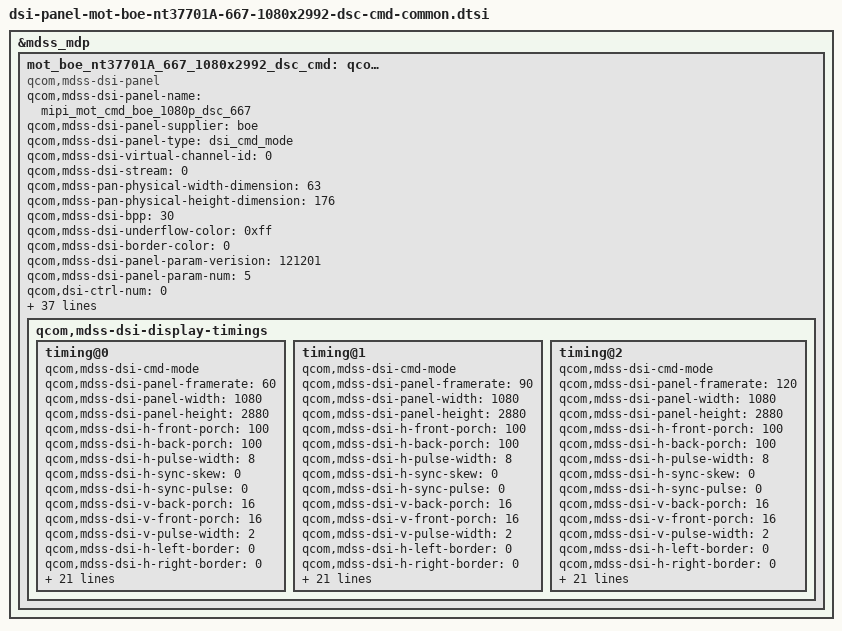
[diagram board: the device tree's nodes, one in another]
/*
 * Copyright (c) 2022, The Linux Foundation. All rights reserved.
 *
 * This program is free software; you can redistribute it and/or modify
 * it under the terms of the GNU General Public License version 2 and
 * only version 2 as published by the Free Software Foundation.
 *
 * This program is distributed in the hope that it will be useful,
 * but WITHOUT ANY WARRANTY; without even the implied warranty of
 * MERCHANTABILITY or FITNESS FOR A PARTICULAR PURPOSE.  See the
 * GNU General Public License for more details.
 */

&mdss_mdp {
mot_boe_nt37701A_667_1080x2992_dsc_cmd: qcom,mdss_dsi_mot_boe_nt37701A_667_1080x2992_dsc_cmd {
compatible = "qcom,mdss-dsi-panel";
qcom,mdss-dsi-panel-name = "mipi_mot_cmd_boe_1080p_dsc_667";
qcom,mdss-dsi-panel-supplier = "boe";
qcom,mdss-dsi-panel-type = "dsi_cmd_mode";
qcom,mdss-dsi-virtual-channel-id = <0>;
qcom,mdss-dsi-stream = <0>;
qcom,mdss-pan-physical-width-dimension = <63>;
qcom,mdss-pan-physical-height-dimension = <176>;
qcom,mdss-dsi-bpp = <30>;
qcom,mdss-dsi-underflow-color = <0xff>;
qcom,mdss-dsi-border-color = <0>;
qcom,mdss-dsi-panel-param-verision = <121201>;
qcom,mdss-dsi-panel-param-num = <5>;

qcom,dsi-ctrl-num = <0>;
qcom,dsi-phy-num = <0>;

qcom,mdss-dsi-traffic-mode = "burst_mode";
qcom,mdss-dsi-bllp-eof-power-mode;
qcom,mdss-dsi-bllp-power-mode;
qcom,mdss-dsi-lane-0-state;
qcom,mdss-dsi-lane-1-state;
qcom,mdss-dsi-lane-2-state;
qcom,mdss-dsi-lane-3-state;

qcom,mdss-dsi-dma-trigger = "trigger_sw";
qcom,mdss-dsi-mdp-trigger = "none";
qcom,mdss-dsi-reset-sequence = <0 11>, <1 1>, <0 1>, <1 11>;
qcom,mdss-dsi-lp11-init;
qcom,mdss-dsi-tx-eot-append;
qcom,mdss-dsi-te-pin-select = <1>;
qcom,mdss-dsi-te-dcs-command = <1>;
qcom,mdss-dsi-te-using-te-pin;

//qcom,bklt-dcs-2bytes-enabled;
qcom,mdss-dsi-bl-min-level = <3>;
qcom,mdss-dsi-bl-max-level = <2047>;
qcom,mdss-dsi-bl-pmic-control-type = "bl_ctrl_dcs";

qcom,mdss-dsi-panel-hdr-enabled;
qcom,mdss-dsi-panel-hdr-color-primaries = <14500 15500 32000
	        17000 15500 30000 8000 3000>;
qcom,mdss-dsi-panel-peak-brightness = <4200000>;

qcom,mdss-dsi-panel-blackness-level = <3230>;

qcom,mdss-dsi-hbm-on-command = [
		39 00 00 00 00 00 03 51 0F FF];
qcom,mdss-dsi-hbm-off-command = [
		39 00 00 00 00 00 03 51 0D BB];

//qcom,mdss-dsi-acl-on-command = [
//		39 01 00 00 00 00 06 F0 55 AA 52 08 00
//		15 00 00 00 00 00 02 B0 0C
//		15 01 00 00 00 00 02 55 05];
//qcom,mdss-dsi-acl-off-command = [
//		15 01 00 00 00 00 02 55 00];

qcom,mdss-dsi-dc-off-command = [
		39 00 00 00 00 00 06 F0 55 AA 52 08 00
		39 00 00 40 00 00 02 B2 18
		39 00 00 40 00 00 02 6F 0F
		39 00 00 40 00 00 09 B2 60 50 65 E9 85 E9 2F FF
		39 00 00 00 00 00 25 B3 00 01 01 59 01 59 02 1A 02 1A 03 0A 03 0A 04 00 04 00 05 E9 05 E9 05 EA 05 EA 09 08 09 08 0D BB 0D BB 0F FF
		39 00 00 00 00 00 02 58 00
		];

qcom,mdss-dsi-dc-off-command-state = "dsi_hs_mode";
qcom,mdss-dsi-dc-on-command = [
		39 00 00 00 00 00 06 F0 55 AA 52 08 00
		39 00 00 40 00 00 02 B2 98
		39 00 00 40 00 00 02 6F 0F
		39 00 00 40 00 00 09 B2 60 50 60 00 80 00 2F FF
		39 00 00 00 00 00 25 B3 00 00 00 00 00 00 00 00 00 00 00 00 00 00 00 00 00 00 00 00 00 00 00 00 05 EA 09 08 09 08 0D BB 0D BB 0F FF
		39 00 00 00 00 00 02 58 01
		];
qcom,mdss-dsi-dc-on-command-state = "dsi_hs_mode";
qcom,mdss-dsi-display-timings {
	timing@0{
		qcom,mdss-dsi-cmd-mode;
		qcom,mdss-dsi-panel-framerate = <60>;
		qcom,mdss-dsi-panel-width = <1080>;
		qcom,mdss-dsi-panel-height = <2880>;
		qcom,mdss-dsi-h-front-porch = <100>;
		qcom,mdss-dsi-h-back-porch = <100>;
		qcom,mdss-dsi-h-pulse-width = <8>;
		qcom,mdss-dsi-h-sync-skew = <0>;
		qcom,mdss-dsi-h-sync-pulse = <0>;
		qcom,mdss-dsi-v-back-porch = <16>;
		qcom,mdss-dsi-v-front-porch = <16>;
		qcom,mdss-dsi-v-pulse-width = <2>;
		qcom,mdss-dsi-h-left-border = <0>;
		qcom,mdss-dsi-h-right-border = <0>;
		qcom,mdss-dsi-v-top-border = <0>;
		qcom,mdss-dsi-v-bottom-border = <0>;
		qcom,mdss-dsi-panel-jitter = <0x20 0xa>; /* 90fps +/- 2 */
		qcom,mdss-dsi-timing-switch-command = [
			15 01 00 00 10 00 02 2F 01 // 01:60Hz 02:90Hz 03:120Hz
		];

		qcom,mdss-dsi-on-command = [
			39 01 00 00 00 00 06 F0 55 AA 52 08 00
			39 01 00 00 00 00 02 6F 05
			39 01 00 00 00 00 05 B5 7F 2B 1A 32
			39 01 00 00 00 00 02 6F 0B
			39 01 00 00 00 00 04 B5 2B 1F 32
			39 01 00 00 00 00 02 6F 10
			39 01 00 00 00 00 06 B5 1A 1A 1A 1A 1A
			39 01 00 00 00 00 02 6F 16
			39 01 00 00 00 00 06 B5 00 00 00 00 00
			39 01 00 00 00 00 02 6F 1B
			39 01 00 00 00 00 06 B5 00 00 00 00 00
			39 01 00 00 00 00 05 FF AA 55 A5 80
			39 01 00 00 00 00 02 6F 1D
			39 01 00 00 00 00 02 F2 05
			39 01 00 00 00 00 01 35
			39 01 00 00 00 00 02 53 20
			39 01 00 00 00 00 05 51 0D BB 0F FE
			39 01 00 00 00 00 05 2A 00 00 04 37
			39 01 00 00 00 00 05 2B 00 00 0B AF
			39 01 00 00 00 00 03 81 01 19
			39 01 00 00 00 00 02 03 01
			39 01 00 00 00 00 02 90 11
			39 01 00 00 00 00 13 91 AB 28 00 10 C2 00 02 0E 01 84 00 07 06 67 06 5C 10 F0
			39 01 00 00 00 00 01 2C
			39 01 00 00 00 00 02 2F 01
			39 01 00 00 00 00 06 F0 55 AA 52 08 00
			39 01 00 00 00 00 04 C0 66 B3 01
			39 01 00 00 00 00 02 6F 11
			39 01 00 00 00 00 02 C0 30
			39 01 00 00 00 00 06 F0 55 AA 52 08 04
			39 01 00 00 00 00 02 C2 14
			39 01 00 00 00 00 02 B1 02
			39 01 00 00 00 00 02 B2 00
			39 01 00 00 00 00 02 6F 01
			39 01 00 00 00 00 04 B2 00 02 00
			39 01 00 00 00 00 02 6F 04
			39 01 00 00 00 00 04 B2 09 45 C0
			39 01 00 00 00 00 07 B4 01 09 48 00 04 B0
			39 01 00 00 00 00 02 D0 00
			39 01 00 00 00 00 05 FF AA 55 A5 80
			39 01 00 00 00 00 02 6F 20
			39 01 00 00 00 00 02 F7 32
			39 01 00 00 00 00 05 2A 00 00 04 37
			39 01 00 00 00 00 05 2B 00 70 0B AF
			39 01 00 00 00 00 05 30 00 70 0B AF
			39 01 00 00 00 00 05 31 00 00 04 37
			39 01 00 00 00 00 02 63 03
			39 01 00 00 00 00 01 12
			05 01 00 00 78 00 01 11
			05 01 00 00 00 00 01 29];	/* display on */
		qcom,mdss-dsi-off-command = [
			05 01 00 00 00 00 01 28		/* display_off */
			05 01 00 00 78 00 01 10];	/* enter sleep mode */

		qcom,mdss-dsi-on-command-state = "dsi_lp_mode";
		qcom,mdss-dsi-off-command-state = "dsi_lp_mode";
		qcom,mdss-dsi-timing-switch-command-state =
			"dsi_lp_mode";
		qcom,compression-mode = "dsc";
		/* Why QCOM doesn't use this, even it used 2 encoder
		 * as for that dsi_sw43404_amoled_cmd, for ex */
		/* qcom,mdss-dsc-encoders = <2>; */
		qcom,mdss-dsc-version = <0x11>;
		qcom,mdss-dsc-slice-height = <16>;
		qcom,mdss-dsc-slice-width = <540>;
		qcom,mdss-dsc-slice-per-pkt = <2>;
		qcom,mdss-dsc-bit-per-component = <10>;
		qcom,mdss-dsc-bit-per-pixel = <8>;
		qcom,mdss-dsc-block-prediction-enable;
	};
	timing@1{
		qcom,mdss-dsi-cmd-mode;
		qcom,mdss-dsi-panel-framerate = <90>;
		qcom,mdss-dsi-panel-width = <1080>;
		qcom,mdss-dsi-panel-height = <2880>;
		qcom,mdss-dsi-h-front-porch = <100>;
		qcom,mdss-dsi-h-back-porch = <100>;
		qcom,mdss-dsi-h-pulse-width = <8>;
		qcom,mdss-dsi-h-sync-skew = <0>;
		qcom,mdss-dsi-h-sync-pulse = <0>;
		qcom,mdss-dsi-v-back-porch = <16>;
		qcom,mdss-dsi-v-front-porch = <16>;
		qcom,mdss-dsi-v-pulse-width = <2>;
		qcom,mdss-dsi-h-left-border = <0>;
		qcom,mdss-dsi-h-right-border = <0>;
		qcom,mdss-dsi-v-top-border = <0>;
		qcom,mdss-dsi-v-bottom-border = <0>;
		qcom,mdss-dsi-panel-jitter = <0x20 0xa>; /* 90fps +/- 2 */
		qcom,mdss-dsi-timing-switch-command = [
			15 01 00 00 10 00 02 2F 02 // 01:60Hz 02:90Hz 03:120Hz
		];

		qcom,mdss-dsi-on-command = [
			39 01 00 00 00 00 06 F0 55 AA 52 08 00
			39 01 00 00 00 00 02 6F 05
			39 01 00 00 00 00 05 B5 7F 2B 1A 32
			39 01 00 00 00 00 02 6F 0B
			39 01 00 00 00 00 04 B5 2B 1F 32
			39 01 00 00 00 00 02 6F 10
			39 01 00 00 00 00 06 B5 1A 1A 1A 1A 1A
			39 01 00 00 00 00 02 6F 16
			39 01 00 00 00 00 06 B5 00 00 00 00 00
			39 01 00 00 00 00 02 6F 1B
			39 01 00 00 00 00 06 B5 00 00 00 00 00
			39 01 00 00 00 00 05 FF AA 55 A5 80
			39 01 00 00 00 00 02 6F 1D
			39 01 00 00 00 00 02 F2 05
			39 01 00 00 00 00 01 35
			39 01 00 00 00 00 02 53 20
			39 01 00 00 00 00 05 51 0D BB 0F FE
			39 01 00 00 00 00 05 2A 00 00 04 37
			39 01 00 00 00 00 05 2B 00 00 0B AF
			39 01 00 00 00 00 03 81 01 19
			39 01 00 00 00 00 02 03 01
			39 01 00 00 00 00 02 90 11
			39 01 00 00 00 00 13 91 AB 28 00 10 C2 00 02 0E 01 84 00 07 06 67 06 5C 10 F0
			39 01 00 00 00 00 01 2C
			39 01 00 00 00 00 02 2F 02
			39 01 00 00 00 00 06 F0 55 AA 52 08 00
			39 01 00 00 00 00 04 C0 66 B3 01
			39 01 00 00 00 00 02 6F 11
			39 01 00 00 00 00 02 C0 30
			39 01 00 00 00 00 06 F0 55 AA 52 08 04
			39 01 00 00 00 00 02 C2 14
			39 01 00 00 00 00 02 B1 02
			39 01 00 00 00 00 02 B2 00
			39 01 00 00 00 00 02 6F 01
			39 01 00 00 00 00 04 B2 00 02 00
			39 01 00 00 00 00 02 6F 04
			39 01 00 00 00 00 04 B2 09 45 C0
			39 01 00 00 00 00 07 B4 01 09 48 00 04 B0
			39 01 00 00 00 00 02 D0 00
			39 01 00 00 00 00 05 FF AA 55 A5 80
			39 01 00 00 00 00 02 6F 20
			39 01 00 00 00 00 02 F7 32
			39 01 00 00 00 00 05 2A 00 00 04 37
			39 01 00 00 00 00 05 2B 00 70 0B AF
			39 01 00 00 00 00 05 30 00 70 0B AF
			39 01 00 00 00 00 05 31 00 00 04 37
			39 01 00 00 00 00 02 63 03
			39 01 00 00 00 00 01 12
			05 01 00 00 78 00 01 11
			05 01 00 00 00 00 01 29];	/* display on */
		qcom,mdss-dsi-off-command = [
			05 01 00 00 00 00 01 28		/* display_off */
			05 01 00 00 78 00 01 10];	/* enter sleep mode */

		qcom,mdss-dsi-on-command-state = "dsi_lp_mode";
		qcom,mdss-dsi-off-command-state = "dsi_lp_mode";
		qcom,mdss-dsi-timing-switch-command-state =
			"dsi_lp_mode";
		qcom,compression-mode = "dsc";
		/* Why QCOM doesn't use this, even it used 2 encoder
		 * as for that dsi_sw43404_amoled_cmd, for ex */
		/* qcom,mdss-dsc-encoders = <2>; */
		qcom,mdss-dsc-version = <0x11>;
		qcom,mdss-dsc-slice-height = <16>;
		qcom,mdss-dsc-slice-width = <540>;
		qcom,mdss-dsc-slice-per-pkt = <2>;
		qcom,mdss-dsc-bit-per-component = <10>;
		qcom,mdss-dsc-bit-per-pixel = <8>;
		qcom,mdss-dsc-block-prediction-enable;
	};
	timing@2{
		qcom,mdss-dsi-cmd-mode;
		qcom,mdss-dsi-panel-framerate = <120>;
		qcom,mdss-dsi-panel-width = <1080>;
		qcom,mdss-dsi-panel-height = <2880>;
		qcom,mdss-dsi-h-front-porch = <100>;
		qcom,mdss-dsi-h-back-porch = <100>;
		qcom,mdss-dsi-h-pulse-width = <8>;
		qcom,mdss-dsi-h-sync-skew = <0>;
		qcom,mdss-dsi-h-sync-pulse = <0>;
		qcom,mdss-dsi-v-back-porch = <16>;
		qcom,mdss-dsi-v-front-porch = <16>;
		qcom,mdss-dsi-v-pulse-width = <2>;
		qcom,mdss-dsi-h-left-border = <0>;
		qcom,mdss-dsi-h-right-border = <0>;
		qcom,mdss-dsi-v-top-border = <0>;
		qcom,mdss-dsi-v-bottom-border = <0>;
		qcom,mdss-dsi-panel-jitter = <0x20 0xa>; /* 90fps +/- 2 */
		qcom,mdss-dsi-timing-switch-command = [
			15 01 00 00 10 00 02 2F 03 // 01:60Hz 02:90Hz 03:120Hz
		];

		qcom,mdss-dsi-on-command = [
			39 01 00 00 00 00 06 F0 55 AA 52 08 00
			39 01 00 00 00 00 02 6F 05
			39 01 00 00 00 00 05 B5 7F 2B 1A 32
			39 01 00 00 00 00 02 6F 0B
			39 01 00 00 00 00 04 B5 2B 1F 32
			39 01 00 00 00 00 02 6F 10
			39 01 00 00 00 00 06 B5 1A 1A 1A 1A 1A
			39 01 00 00 00 00 02 6F 16
			39 01 00 00 00 00 06 B5 00 00 00 00 00
			39 01 00 00 00 00 02 6F 1B
			39 01 00 00 00 00 06 B5 00 00 00 00 00
			39 01 00 00 00 00 05 FF AA 55 A5 80
			39 01 00 00 00 00 02 6F 1D
			39 01 00 00 00 00 02 F2 05
			39 01 00 00 00 00 01 35
			39 01 00 00 00 00 02 53 20
			39 01 00 00 00 00 05 51 0D BB 0F FE
			39 01 00 00 00 00 05 2A 00 00 04 37
			39 01 00 00 00 00 05 2B 00 00 0B AF
			39 01 00 00 00 00 03 81 01 19
			39 01 00 00 00 00 02 03 01
			39 01 00 00 00 00 02 90 11
			39 01 00 00 00 00 13 91 AB 28 00 10 C2 00 02 0E 01 84 00 07 06 67 06 5C 10 F0
			39 01 00 00 00 00 01 2C
			39 01 00 00 00 00 02 2F 03
			39 01 00 00 00 00 06 F0 55 AA 52 08 00
			39 01 00 00 00 00 04 C0 66 B3 01
			39 01 00 00 00 00 02 6F 11
			39 01 00 00 00 00 02 C0 30
			39 01 00 00 00 00 06 F0 55 AA 52 08 04
			39 01 00 00 00 00 02 C2 14
			39 01 00 00 00 00 02 B1 02
			39 01 00 00 00 00 02 B2 00
			39 01 00 00 00 00 02 6F 01
			39 01 00 00 00 00 04 B2 00 02 00
			39 01 00 00 00 00 02 6F 04
			39 01 00 00 00 00 04 B2 09 45 C0
			39 01 00 00 00 00 07 B4 01 09 48 00 04 B0
			39 01 00 00 00 00 02 D0 00
			39 01 00 00 00 00 05 FF AA 55 A5 80
			39 01 00 00 00 00 02 6F 20
			39 01 00 00 00 00 02 F7 32
			39 01 00 00 00 00 05 2A 00 00 04 37
			39 01 00 00 00 00 05 2B 00 70 0B AF
			39 01 00 00 00 00 05 30 00 70 0B AF
			39 01 00 00 00 00 05 31 00 00 04 37
			39 01 00 00 00 00 02 63 03
			39 01 00 00 00 00 01 12
			05 01 00 00 78 00 01 11
			05 01 00 00 00 00 01 29];	/* display on */
		qcom,mdss-dsi-off-command = [
			05 01 00 00 00 00 01 28		/* display_off */
			05 01 00 00 78 00 01 10];	/* enter sleep mode */

		qcom,mdss-dsi-on-command-state = "dsi_lp_mode";
		qcom,mdss-dsi-off-command-state = "dsi_lp_mode";
		qcom,mdss-dsi-timing-switch-command-state =
			"dsi_lp_mode";
		qcom,compression-mode = "dsc";
		/* Why QCOM doesn't use this, even it used 2 encoder
		 * as for that dsi_sw43404_amoled_cmd, for ex */
		/* qcom,mdss-dsc-encoders = <2>; */
		qcom,mdss-dsc-version = <0x11>;
		qcom,mdss-dsc-slice-height = <16>;
		qcom,mdss-dsc-slice-width = <540>;
		qcom,mdss-dsc-slice-per-pkt = <2>;
		qcom,mdss-dsc-bit-per-component = <10>;
		qcom,mdss-dsc-bit-per-pixel = <8>;
		qcom,mdss-dsc-block-prediction-enable;
	};
};

};

};
